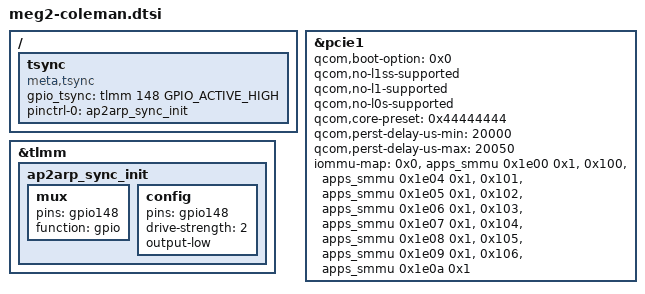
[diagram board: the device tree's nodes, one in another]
// SPDX-License-Identifier: GPL-2.0

#include <dt-bindings/clock/qcom,rpmh.h>

/ {
	fragment@model {
		target-path = "/";
		__overlay__ {
			tsync {
				compatible = "meta,tsync";
				gpio_tsync = <&tlmm 148 GPIO_ACTIVE_HIGH>;
				pinctrl-names = "default";
				pinctrl-0 = <&ap2arp_sync_init>;
			};
		}; /* end of __overlay__ */
	}; /* end of fragment */
};

&pcie1 {
	status = "ok";
	// Auto enumerate Avo device.
	qcom,boot-option = <0x0>;
	qcom,no-l1ss-supported; // l1ss is still buggy
	qcom,no-l1-supported; // l1ss is still buggy

	// note: this is defined in the vendor supplied dts, so
	// disabling it here by itself wont help, you need to
	// also disable it in kona-pcie.dtsi.
	qcom,no-l0s-supported; // l0s is potentially buggy

	// Default to no preshoot or deemphasis.
	// This is the seed value for link training and lowers
	// the default starting drive strength. On HFD, enumeration
	// fails without this configuration.
	qcom,core-preset = <0x44444444>;

	// Avo requires 20ms between PERST deassertion and link training
	qcom,perst-delay-us-min = <20000>;
	qcom,perst-delay-us-max = <20050>;

	iommu-map = <0x0 &apps_smmu 0x1e00 0x1>,
		<0x100 &apps_smmu 0x1e04 0x1>,
		<0x101 &apps_smmu 0x1e05 0x1>,
		<0x102 &apps_smmu 0x1e06 0x1>,
		<0x103 &apps_smmu 0x1e07 0x1>,
		<0x104 &apps_smmu 0x1e08 0x1>,
		<0x105 &apps_smmu 0x1e09 0x1>,
		<0x106 &apps_smmu 0x1e0a 0x1>;
};

&tlmm {
	ap2arp_sync_init: ap2arp_sync_init {
		mux {
			pins = "gpio148";
			function = "gpio";
		};

		config {
			pins = "gpio148";
			drive-strength = <2>;
			output-low;
		};
	};
};
